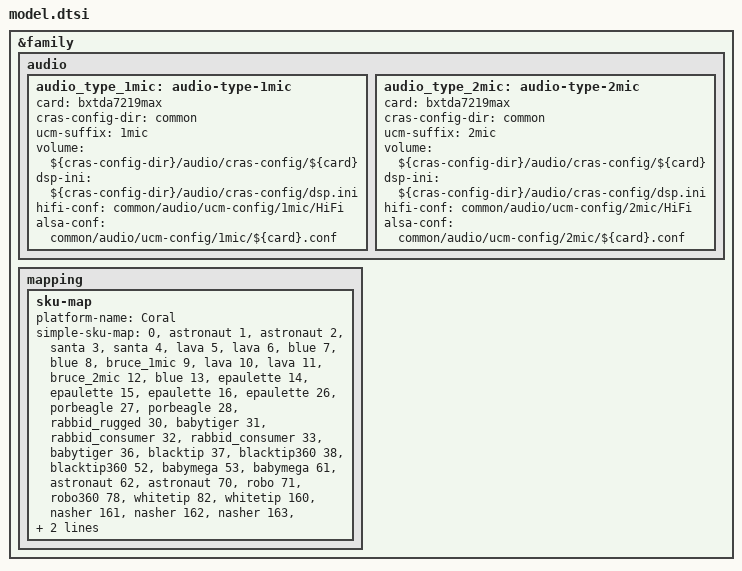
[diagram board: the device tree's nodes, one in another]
/*
 * Copyright 2017 The Chromium OS Authors. All rights reserved.
 *
 * Use of this source code is governed by a BSD-style license that can be
 * found in the LICENSE file.
 */

&family {
	audio {
		audio_type_1mic: audio-type-1mic {
			card = "bxtda7219max";
			cras-config-dir = "common";
			ucm-suffix = "1mic";
			volume = "${cras-config-dir}/audio/cras-config/${card}";
			dsp-ini = "${cras-config-dir}/audio/cras-config/dsp.ini";
			hifi-conf = "common/audio/ucm-config/1mic/HiFi";
			alsa-conf = "common/audio/ucm-config/1mic/${card}.conf";
		};

		audio_type_2mic: audio-type-2mic {
			card = "bxtda7219max";
			cras-config-dir = "common";
			ucm-suffix = "2mic";
			volume = "${cras-config-dir}/audio/cras-config/${card}";
			dsp-ini = "${cras-config-dir}/audio/cras-config/dsp.ini";
			hifi-conf = "common/audio/ucm-config/2mic/HiFi";
			alsa-conf = "common/audio/ucm-config/2mic/${card}.conf";
		};
	};

	mapping {
		/*
		 * For now we only map to model. We can change this to
		 * sub-model if needed.
		 */
		sku-map {
			platform-name = "Coral";
			simple-sku-map = < 0 &astronaut
				1 &astronaut
				2 &santa
				3 &santa
				4 &lava
				5 &lava
				6 &blue
				7 &blue
				8 &bruce_1mic
				9 &lava
				10 &lava
				11 &bruce_2mic
				12 &blue
				13 &epaulette
				14 &epaulette
				15 &epaulette
				16 &epaulette
				26 &porbeagle
				27 &porbeagle
				28 &rabbid_rugged
				30 &babytiger
				31 &rabbid_consumer
				32 &rabbid_consumer
				33 &babytiger
				36 &blacktip
				37 &blacktip360
				38 &blacktip360
				52 &babymega
				53 &babymega
				61 &astronaut
				62 &astronaut
				70 &robo
				71 &robo360
				78 &whitetip
				82 &whitetip
				160 &nasher
				161 &nasher
				162 &nasher
				163 &nasher360_1mic
				164 &nasher360_1mic
				165 &nasher360_2mic
				166 &nasher360_2mic
			>;
		};
	};
};
